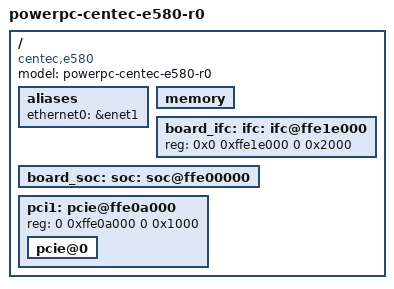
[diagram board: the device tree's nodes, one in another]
/*
 * CTC Platform P1010 Board Device Tree Source
 *
 * Copyright (C) 2005 Centec Networks Inc.  All rights reserved.
 *
 * This program is free software; you can redistribute  it and/or modify it
 * under  the terms of  the GNU General  Public License as published by the
 * Free Software Foundation;  either version 2 of the  License, or (at your
 * option) any later version.
 */

/include/ "fsl/p1010_ctc_si-pre.dtsi"

/ {
	model = "powerpc-centec-e580-r0";
	compatible = "centec,e580";
	
	aliases {
		ethernet0 = &enet1; 
	};

	memory {
		device_type = "memory";
	};

	board_ifc: ifc: ifc@ffe1e000 {
		/* NAND Flashes and CPLD on board */
		ranges = <0x0 0x0 0x0 0xeff80000 0x00080000
                          0x1 0x0 0x0 0xff800000 0x00010000
			  0x3 0x0 0x0 0xffb00000 0x00010000>;
		reg = <0x0 0xffe1e000 0 0x2000>;
	};

	board_soc: soc: soc@ffe00000 {
		ranges = <0x0  0x0 0xffe00000 0x100000>;
	};

	pci1: pcie@ffe0a000 {
		reg = <0 0xffe0a000 0 0x1000>;
		ranges = <0x2000000 0x0 0x80000000 0 0x80000000 0x0 0x20000000
			  0x1000000 0x0 0x00000000 0 0xffc00000 0x0 0x10000>;
		pcie@0 {
			ranges = <0x2000000 0x0 0x80000000
				  0x2000000 0x0 0x80000000
				  0x0 0x20000000

				  0x1000000 0x0 0x0
				  0x1000000 0x0 0x0
				  0x0 0x100000>;
		};
	};
};

/include/ "powerpc-centec-e580-r0.dtsi"
/include/ "fsl/p1010_ctc_si-post.dtsi"
